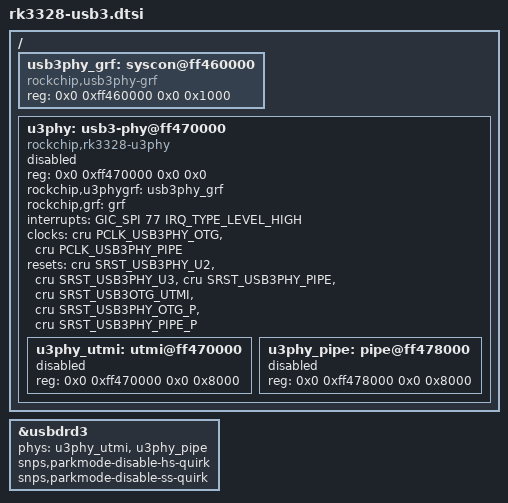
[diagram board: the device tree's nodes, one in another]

/ {
	usb3phy_grf: syscon@ff460000 {
		compatible = "rockchip,usb3phy-grf", "syscon";
		reg = <0x0 0xff460000 0x0 0x1000>;
	};

	u3phy: usb3-phy@ff470000 {
		compatible = "rockchip,rk3328-u3phy";
		reg = <0x0 0xff470000 0x0 0x0>;
		rockchip,u3phygrf = <&usb3phy_grf>;
		rockchip,grf = <&grf>;
		interrupts = <GIC_SPI 77 IRQ_TYPE_LEVEL_HIGH>;
		interrupt-names = "linestate";
		clocks = <&cru PCLK_USB3PHY_OTG>, <&cru PCLK_USB3PHY_PIPE>;
		clock-names = "u3phy-otg", "u3phy-pipe";
		resets = <&cru SRST_USB3PHY_U2>,
			 <&cru SRST_USB3PHY_U3>,
			 <&cru SRST_USB3PHY_PIPE>,
			 <&cru SRST_USB3OTG_UTMI>,
			 <&cru SRST_USB3PHY_OTG_P>,
			 <&cru SRST_USB3PHY_PIPE_P>;
		reset-names = "u3phy-u2-por", "u3phy-u3-por",
			      "u3phy-pipe-mac", "u3phy-utmi-mac",
			      "u3phy-utmi-apb", "u3phy-pipe-apb";
		#address-cells = <2>;
		#size-cells = <2>;
		ranges;
		status = "disabled";

		u3phy_utmi: utmi@ff470000 {
			reg = <0x0 0xff470000 0x0 0x8000>;
			#phy-cells = <0>;
			status = "disabled";
		};

		u3phy_pipe: pipe@ff478000 {
			reg = <0x0 0xff478000 0x0 0x8000>;
			#phy-cells = <0>;
			status = "disabled";
		};
	};
};

&usbdrd3 {
	phys = <&u3phy_utmi>, <&u3phy_pipe>;
	phy-names = "usb2-phy", "usb3-phy";
	snps,parkmode-disable-hs-quirk;
	snps,parkmode-disable-ss-quirk;
};
